# STM32WLE4C8U6 register map
File version: 1.0
Registers are 32-bit, access not given, reset 0x0 unless marked. A register's access mark holds for its fields unless they carry their own. Offsets are from the block's base; [hi:lo] are bit positions; {n}, {i} and the like mark numbered series.

## GPIO
Base 0x48000800
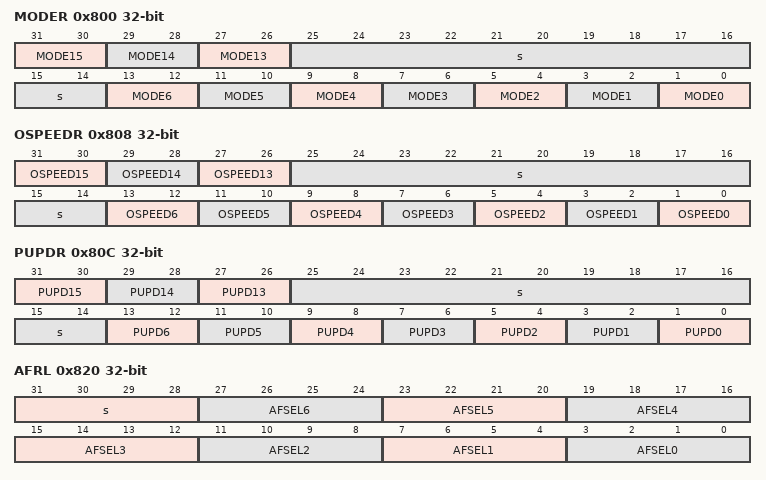
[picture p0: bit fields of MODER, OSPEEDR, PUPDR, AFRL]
0x800 MODER
  [31:30] MODE15, [29:28] MODE14, [27:26] MODE13, [25:14] s, [2n+1:2n] MODE{n} (n=0..6)
0x804 OTYPER
  [15] OT15, [14] OT14, [13] OT13, [31:7] s, [n] OT{n} (n=0..6)
0x808 OSPEEDR
  [31:30] OSPEED15, [29:28] OSPEED14, [27:26] OSPEED13, [25:14] s, [2n+1:2n] OSPEED{n} (n=0..6)
0x80C PUPDR
  [31:30] PUPD15, [29:28] PUPD14, [27:26] PUPD13, [25:14] s, [2n+1:2n] PUPD{n} (n=0..6)
0x810 IDR
  [15] ID15, [14] ID14, [13] ID13, [31:7] s, [n] ID{n} (n=0..6)
0x814 ODR
  [15] OD15, [14] OD14, [13] OD13, [31:7] s, [n] OD{n} (n=0..6)
0x818 BSRR
  [31] BR15, [30] BR14, [29] BR13, [n+16] BR{n} (n=0..6), [15] BS15, [14] BS14, [13] BS13, [28:7] s, [n] BS{n} (n=0..6)
0x81C LCKR
  [16] LCKK, [15] LCK15, [14] LCK14, [13] LCK13, [31:7] s, [n] LCK{n} (n=0..6)
0x820 AFRL
  [31:28] s, [4n+3:4n] AFSEL{n} (n=0..6)
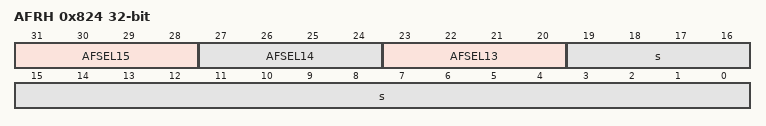
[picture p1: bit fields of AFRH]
0x824 AFRH
  [31:28] AFSEL15, [27:24] AFSEL14, [23:20] AFSEL13, [19:0] s
0x828 BRR
  [15] BR15, [14] BR14, [13] BR13, [31:7] s, [n] BR{n} (n=0..6)
